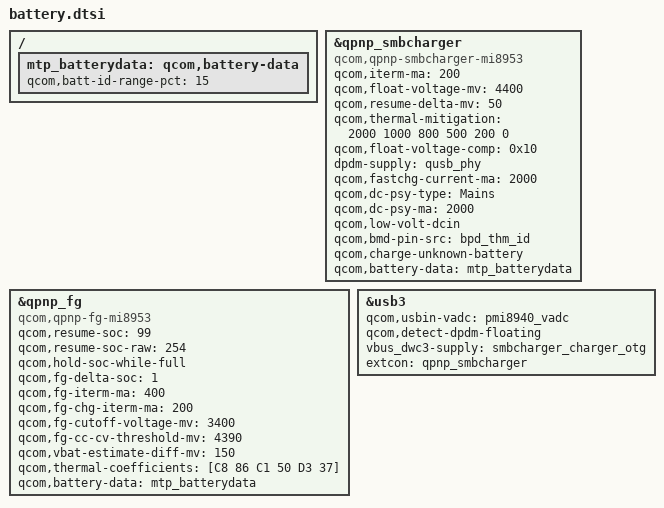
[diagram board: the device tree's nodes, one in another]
/{
	mtp_batterydata: qcom,battery-data {
		qcom,batt-id-range-pct = <15>;
        	#include "../common/batterydata/batterydata-coslight-3000mah.dtsi"
        	#include "../common/batterydata/batterydata-sunwoda-3000mah.dtsi"
        	#include "../common/batterydata/batterydata-share-3000mah.dtsi"
	};
};

&qpnp_smbcharger {
	compatible = "qcom,qpnp-smbcharger-mi8953";

	qcom,iterm-ma = <200>;
	qcom,float-voltage-mv = <4400>;
	qcom,resume-delta-mv = <50>;
	qcom,thermal-mitigation = <2000 1000 800 500 200 0>;
	qcom,float-voltage-comp = <0x10>; /*add comp to 4.1v*/
	dpdm-supply = <&qusb_phy>;
	/delete-property/ qcom,external-typec;
	/delete-property/ qcom,typec-psy-name;
	/delete-property/ qcom,autoadjust-vfloat;
	qcom,fastchg-current-ma = <2000>;
	qcom,dc-psy-type = "Mains";
	qcom,dc-psy-ma = <2000>;
	qcom,low-volt-dcin;
	qcom,bmd-pin-src = "bpd_thm_id";
	qcom,charge-unknown-battery;
	qcom,battery-data = <&mtp_batterydata>;
	/delete-property/ qcom,chg-led-sw-controls;
	/delete-property/ qcom,chg-led-support;
	status = "okay";
};

&qpnp_fg {
	compatible = "qcom,qpnp-fg-mi8953";

	qcom,resume-soc = <99>;
	qcom,resume-soc-raw = <254>;
	qcom,hold-soc-while-full;
	qcom,fg-delta-soc = <1>; //fg soc update frequency
	qcom,fg-iterm-ma = <400>;
	qcom,fg-chg-iterm-ma = <200>; /*default 100ma*/
	qcom,fg-cutoff-voltage-mv = <3400>;
	qcom,fg-cc-cv-threshold-mv = <4390>;
	qcom,vbat-estimate-diff-mv = <150>;
	qcom,thermal-coefficients = [C8 86 C1 50 D3 37];
	/delete-property/ qcom,capacity-learning-on;
	qcom,battery-data = <&mtp_batterydata>;
	status = "okay";
};

&usb3 {
	qcom,usbin-vadc = <&pmi8940_vadc>;
	qcom,detect-dpdm-floating;
	vbus_dwc3-supply = <&smbcharger_charger_otg>;
	extcon = <&qpnp_smbcharger>;
};
